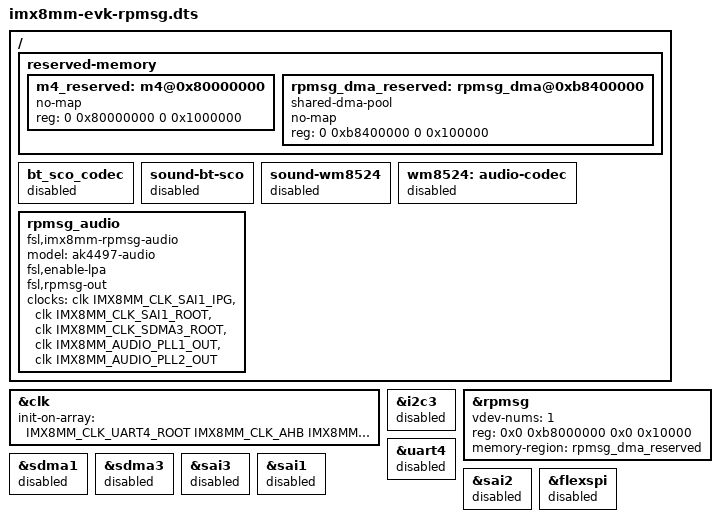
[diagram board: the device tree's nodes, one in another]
// SPDX-License-Identifier: (GPL-2.0 OR MIT)
/*
 * Copyright 2019 NXP
 */

/dts-v1/;

#include "imx8mm-evk.dts"

/ {
	reserved-memory {
		#address-cells = <2>;
		#size-cells = <2>;
		ranges;

		m4_reserved: m4@0x80000000 {
			no-map;
			reg = <0 0x80000000 0 0x1000000>;
		};

		rpmsg_dma_reserved:rpmsg_dma@0xb8400000 {
			compatible = "shared-dma-pool";
			no-map;
			reg = <0 0xb8400000 0 0x100000>;
		};
	};

	bt_sco_codec: bt_sco_codec {
		status = "disabled";
	};

	sound-bt-sco {
		status = "disabled";
	};

	sound-wm8524 {
		status = "disabled";
	};

	wm8524: audio-codec {
		status = "disabled";
	};

	rpmsg_audio: rpmsg_audio {
		compatible = "fsl,imx8mm-rpmsg-audio";
		model = "ak4497-audio";
		fsl,enable-lpa;
		fsl,rpmsg-out;
		clocks = <&clk IMX8MM_CLK_SAI1_IPG>,
			 <&clk IMX8MM_CLK_SAI1_ROOT>,
			 <&clk IMX8MM_CLK_SDMA3_ROOT>,
			 <&clk IMX8MM_AUDIO_PLL1_OUT>,
			 <&clk IMX8MM_AUDIO_PLL2_OUT>;
		clock-names = "bus", "mclk", "dma", "pll8k", "pll11k";
		status = "okay";
	};
};

&clk {
	init-on-array = <IMX8MM_CLK_UART4_ROOT
	IMX8MM_CLK_AHB IMX8MM_CLK_DRAM_CORE
	IMX8MM_CLK_NOC IMX8MM_CLK_NOC_APB
	IMX8MM_CLK_USB_BUS
	IMX8MM_CLK_MAIN_AXI IMX8MM_CLK_AUDIO_AHB
	IMX8MM_CLK_DRAM_APB IMX8MM_CLK_A53_DIV
	IMX8MM_ARM_PLL_OUT IMX8MM_CLK_DISP_AXI
	IMX8MM_CLK_DISP_APB
	>;
};

/*
 * ATTENTION: M4 may use IPs like below
 * ECSPI0/ECSPI2, GPIO1/GPIO5, GPT1, I2C3, I2S3, WDOG1, UART4, PWM3, SDMA1
 */

&i2c3 {
	status = "disabled";
};

&rpmsg{
	/*
	 * 64K for one rpmsg instance:
	 * --0xb8000000~0xb800ffff: pingpong
	 */
	vdev-nums = <1>;
	reg = <0x0 0xb8000000 0x0 0x10000>;
	memory-region = <&rpmsg_dma_reserved>;
	status = "okay";
};

&sdma1{
	status = "disabled";
};

&uart4 {
	status = "disabled";
};

&sdma3 {
	status = "disabled";
};

&sai3 {
	status = "disabled";
};

&sai1 {
	status = "disabled";
};

&sai2 {
	status = "disabled";
};

&flexspi {
	status = "disabled";
};
